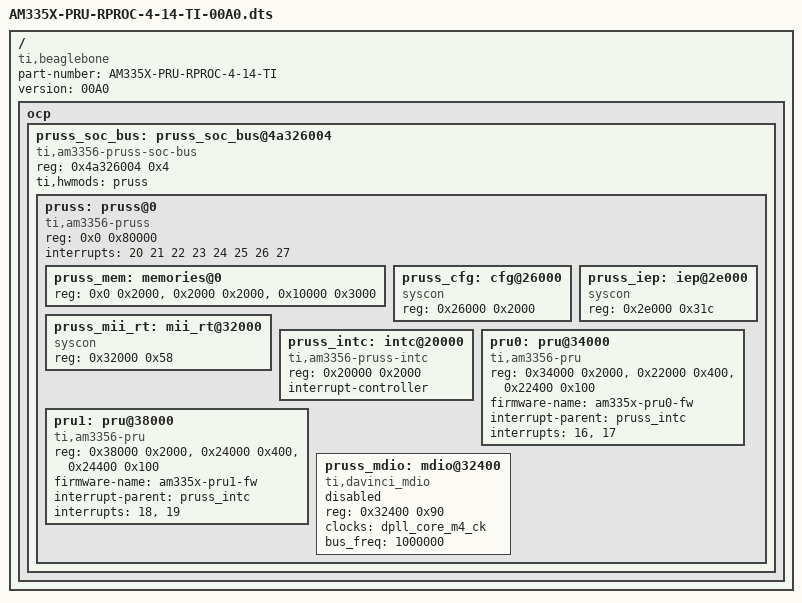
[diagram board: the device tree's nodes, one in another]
/*
 * Copyright (C) 2015 Texas Instruments Incorporated - http://www.ti.com/
 *
 * This program is free software; you can redistribute it and/or modify
 * it under the terms of the GNU General Public License version 2 as
 * published by the Free Software Foundation.
 */
/dts-v1/;
/plugin/;

/ {
	compatible = "ti,beaglebone", "ti,beaglebone-black", "ti,beaglebone-green";

	// identification
	part-number = "AM335X-PRU-RPROC-4-14-TI";
	version = "00A0";

	fragment@0 {
		target-path="/";
		__overlay__ {

			ocp {
				#address-cells = <1>;
				#size-cells = <1>;

				pruss_soc_bus: pruss_soc_bus@4a326004 {
					compatible = "ti,am3356-pruss-soc-bus";
					reg = <0x4a326004 0x4>;
					ti,hwmods = "pruss";
					#address-cells = <1>;
					#size-cells = <1>;
					ranges = <0x0 0x4a300000 0x80000>;
					status = "okay";

					pruss: pruss@0 {
						compatible = "ti,am3356-pruss";
						reg = <0x0 0x80000>;
						interrupts = <20 21 22 23 24 25 26 27>;
						interrupt-names = "host2", "host3", "host4",
								  "host5", "host6", "host7",
								  "host8", "host9";
						#address-cells = <1>;
						#size-cells = <1>;
						ranges;
						status = "okay";

						pruss_mem: memories@0 {
							reg = <0x0 0x2000>,
							      <0x2000 0x2000>,
							      <0x10000 0x3000>;
							reg-names = "dram0", "dram1",
								    "shrdram2";
						};

						pruss_cfg: cfg@26000 {
							compatible = "syscon";
							reg = <0x26000 0x2000>;
						};

						pruss_iep: iep@2e000 {
							compatible = "syscon";
							reg = <0x2e000 0x31c>;
						};

						pruss_mii_rt: mii_rt@32000 {
							compatible = "syscon";
							reg = <0x32000 0x58>;
						};

						pruss_intc: intc@20000 {
							compatible = "ti,am3356-pruss-intc";
							reg = <0x20000 0x2000>;
							reg-names = "intc";
							interrupt-controller;
							#interrupt-cells = <1>;
						};

						pru0: pru@34000 {
							compatible = "ti,am3356-pru";
							reg = <0x34000 0x2000>,
							      <0x22000 0x400>,
							      <0x22400 0x100>;
							reg-names = "iram", "control", "debug";
							firmware-name = "am335x-pru0-fw";
							interrupt-parent = <&pruss_intc>;
							interrupts = <16>, <17>;
							interrupt-names = "vring", "kick";
						};

						pru1: pru@38000 {
							compatible = "ti,am3356-pru";
							reg = <0x38000 0x2000>,
							      <0x24000 0x400>,
							      <0x24400 0x100>;
							reg-names = "iram", "control", "debug";
							firmware-name = "am335x-pru1-fw";
							interrupt-parent = <&pruss_intc>;
							interrupts = <18>, <19>;
							interrupt-names = "vring", "kick";
						};

						pruss_mdio: mdio@32400 {
							compatible = "ti,davinci_mdio";
							reg = <0x32400 0x90>;
							clocks = <&dpll_core_m4_ck>;
							clock-names = "fck";
							bus_freq = <1000000>;
							#address-cells = <1>;
							#size-cells = <0>;
							status = "disabled";
						};
					};
				};
			};
		};
	};
};
